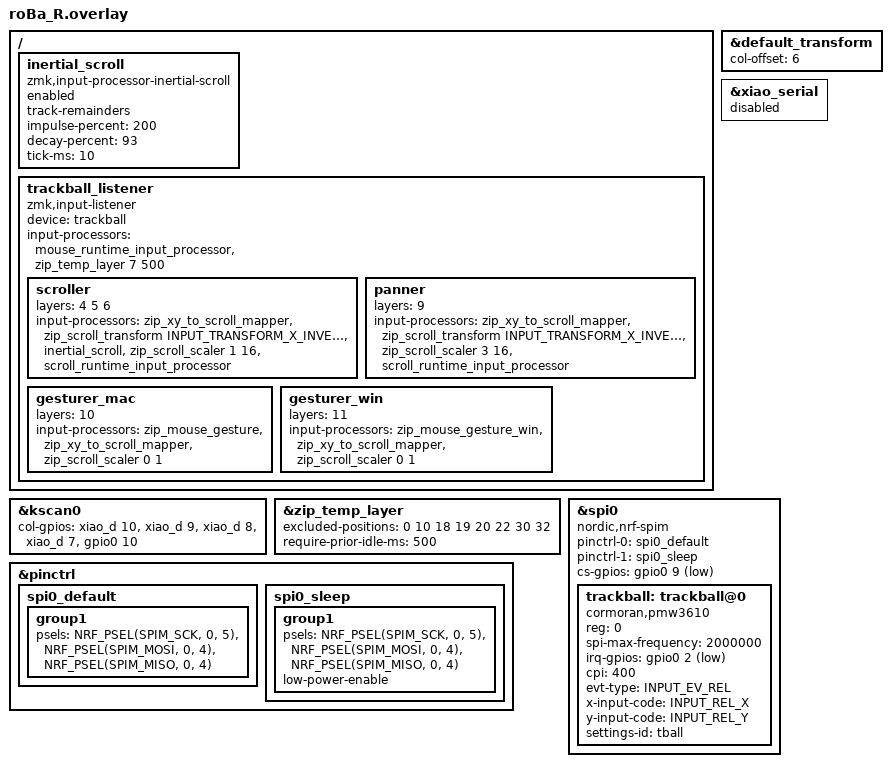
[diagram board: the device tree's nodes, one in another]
#include "roBa.dtsi"
// runtime-input-processor.dtsi は必ず roBa.dtsi の「後ろ」で include すること。
// 同 dtsi は modifiers.h 経由で RC(keycode) を1引数マクロとして再定義し、
// roBa.dtsi のマトリクス RC(row,col) と衝突する。
#include <input/processors/runtime-input-processor.dtsi>
#include <input/processors.dtsi>
#include <zephyr/dt-bindings/input/input-event-codes.h>
#include <dt-bindings/zmk/input_transform.h>

&default_transform {
    col-offset = <6>;
};

&kscan0 {
        col-gpios
            = <&xiao_d 10 GPIO_ACTIVE_HIGH>
            , <&xiao_d 9 GPIO_ACTIVE_HIGH>
            , <&xiao_d 8 GPIO_ACTIVE_HIGH>
            , <&xiao_d 7 GPIO_ACTIVE_HIGH>
            , <&gpio0 10 GPIO_ACTIVE_HIGH>
            ;
};

/ {
    // 慣性スクロール (shakushakupanda/zmk-module-mouse-gesture-rpc)
    // 本家 roBa のドライバには慣性スクロール機能が無く、cormoran 版にも無い。
    // moNa2 と同じく入力プロセッサ方式で足す。
    // 有効範囲は「どのチェーンに挿すか」で決まるので、下の scroller にのみ挿す。
    inertial_scroll: inertial_scroll {
        compatible = "zmk,input-processor-inertial-scroll";
        status = "okay";
        #input-processor-cells = <0>;
        enabled;                    // 既定で有効 (モジュール既定はオフ)
        track-remainders;           // 端数を切り捨てず次のtickへ持ち越す。
                                    // 無いと低速時に値が0に丸められてカクつく
        impulse-percent = <200>;
        decay-percent = <93>;
        tick-ms = <10>;
    };

    trackball_listener {
        status = "okay";
        compatible = "zmk,input-listener";
        device = <&trackball>;

        // 本家(v0.3)はドライバの automouse-layer / scroll-layers プロパティで
        // 実現していたが、cormoran 版ドライバにその機能は無い。
        // v0.4 の入力プロセッサへ移し替えている。
        //
        // 通常時: カーソル移動。ボールを動かすと MOUSE 層を一時有効化
        //   (= 旧 automouse-layer)。moNa2 のキーマップ移植に伴い
        //   MOUSE 層は 4 -> 7 へ移動した。タイムアウトは moNa2 実機で
        //   決めた 500ms を採用 (本家 roBa は 700ms)。
        input-processors = <&mouse_runtime_input_processor &zip_temp_layer 7 500>;

        // NUM(4) / NAV_MAC(5) / NAV_WIN(6) でカーソル移動ではなくスクロールにする
        //   (本家の scroll-layers = <5> に相当。moNa2 の設計に合わせて3層へ拡張)
        scroller {
            layers = <4 5 6>;
            input-processors =
                <&zip_xy_to_scroll_mapper
                 &zip_scroll_transform INPUT_TRANSFORM_X_INVERT
                 &inertial_scroll
                 &zip_scroll_scaler 1 16
                 &scroll_runtime_input_processor>;
            // scaler 1/16 は旧 CONFIG_PMW3610_SCROLL_TICK=16 に対応する値。
            // X反転は旧 CONFIG_PMW3610_INVERT_SCROLL_X=y に対応。
            //
            // 順序が重要: &inertial_scroll は scaler の「前」に置くこと。
            // zip_scroll_scaler には端数を蓄積する仕組みが無いため、後ろに
            // 置くと 1/16 に切り捨てられて 0 になった値に慣性をかけることに
            // なり「ちょびちょび・カクカク」になる (moNa2 で実際に嵌った)。
            //
            // 速度は DYA Studio のトラックボールタブから実行時に調整できる。
        };

        // P長押し(GESTURE_PAN=9): 2D自由スクロール(パン)。
        // ざっと移動する用途なので scroller(1/16) の約3倍にしてある。
        panner {
            layers = <9>;
            input-processors =
                <&zip_xy_to_scroll_mapper
                 &zip_scroll_transform INPUT_TRANSFORM_X_INVERT
                 &zip_scroll_scaler 3 16
                 &scroll_runtime_input_processor>;
        };

        // Q長押し(GESTURE_SNAP_MAC=10): Mac ウィンドウスナップ(Rectangle)
        // zip_xy_to_scroll_mapper + scaler 0/1 は「カーソルを動かさない」ための細工。
        // REL_X/Y を WHEEL に型変換して値を0にすることで、ジェスチャー中の
        // カーソル移動を確実に殺す (PAN と同じ原理)。
        // モジュールの suppress-cursor-while-active は起動キーの押下状態から
        // 抑止フラグを立てる実装なので、always-active の本構成では効かない。
        gesturer_mac {
            layers = <10>;
            input-processors = <
                &zip_mouse_gesture
                &zip_xy_to_scroll_mapper
                &zip_scroll_scaler 0 1
            >;
        };

        // Q長押し(GESTURE_SNAP_WIN=11): Win ウィンドウスナップ(Win+矢印)
        gesturer_win {
            layers = <11>;
            input-processors = <
                &zip_mouse_gesture_win
                &zip_xy_to_scroll_mapper
                &zip_scroll_scaler 0 1
            >;
        };
    };
};

// オートマウスレイヤー(AML)の暴発対策。moNa2 の値をキー位置シフト規則
// (moNa2 の i -> roBa の i<15 ? i : i+1) で移してある:
//   moNa2 <0 10 17 18 19 21 29 31> -> roBa <0 10 18 19 20 22 30 32>
// = Q / A / J K L / X / M . 。これらを押している間はボールが動いても
// MOUSE 層へ移行しない。
&zip_temp_layer {
    excluded-positions = <0 10 18 19 20 22 30 32>;
    require-prior-idle-ms = <500>;  // 打鍵直後この時間はAMLを起こさない
};

&pinctrl {
    spi0_default: spi0_default {
        group1 {
            psels = <NRF_PSEL(SPIM_SCK, 0, 5)>,
                <NRF_PSEL(SPIM_MOSI, 0, 4)>,
                <NRF_PSEL(SPIM_MISO, 0, 4)>;
        };
    };

    spi0_sleep: spi0_sleep {
        group1 {
            psels = <NRF_PSEL(SPIM_SCK, 0, 5)>,
                <NRF_PSEL(SPIM_MOSI, 0, 4)>,
                <NRF_PSEL(SPIM_MISO, 0, 4)>;
            low-power-enable;
        };
    };
};

&xiao_serial { status = "disabled"; };

&spi0 {
    status = "okay";
    compatible = "nordic,nrf-spim";
    pinctrl-0 = <&spi0_default>;
    pinctrl-1 = <&spi0_sleep>;
    pinctrl-names = "default", "sleep";
    cs-gpios = <&gpio0 9 GPIO_ACTIVE_LOW>;

    trackball: trackball@0 {
        status = "okay";
        // ZMK v0.4 (Zephyr 4.1) が純正 "pixart,pmw3610" ドライバを取り込んだため、
        // 旧 compatible は衝突して使えない。cormoran 氏の custom Studio RPC 対応版
        // (compatible = "cormoran,pmw3610") へ移行した。
        compatible = "cormoran,pmw3610";
        reg = <0>;
        spi-max-frequency = <2000000>;
        irq-gpios = <&gpio0 2 (GPIO_ACTIVE_LOW | GPIO_PULL_UP)>;
        // 旧 CONFIG_PMW3610_CPI=400 はここへ移った
        cpi = <400>;
        evt-type = <INPUT_EV_REL>;
        x-input-code = <INPUT_REL_X>;
        y-input-code = <INPUT_REL_Y>;
        // DYA Studio 上でこのセンサーを識別するための短い ID
        settings-id = "tball";
        // 軸の向きは CONFIG_PMW3610_INVERT_X / _INVERT_Y (roBa_R.conf) で指定する。
        // 旧構成の CONFIG_PMW3610_ORIENTATION_180 に相当するものが無いため、
        // 本家 dya-studio ブランチの実機検証に倣って INVERT_Y のみ有効にしている。
        // ★実機で向きが違ったらここが最初の調整箇所★
    };
};
